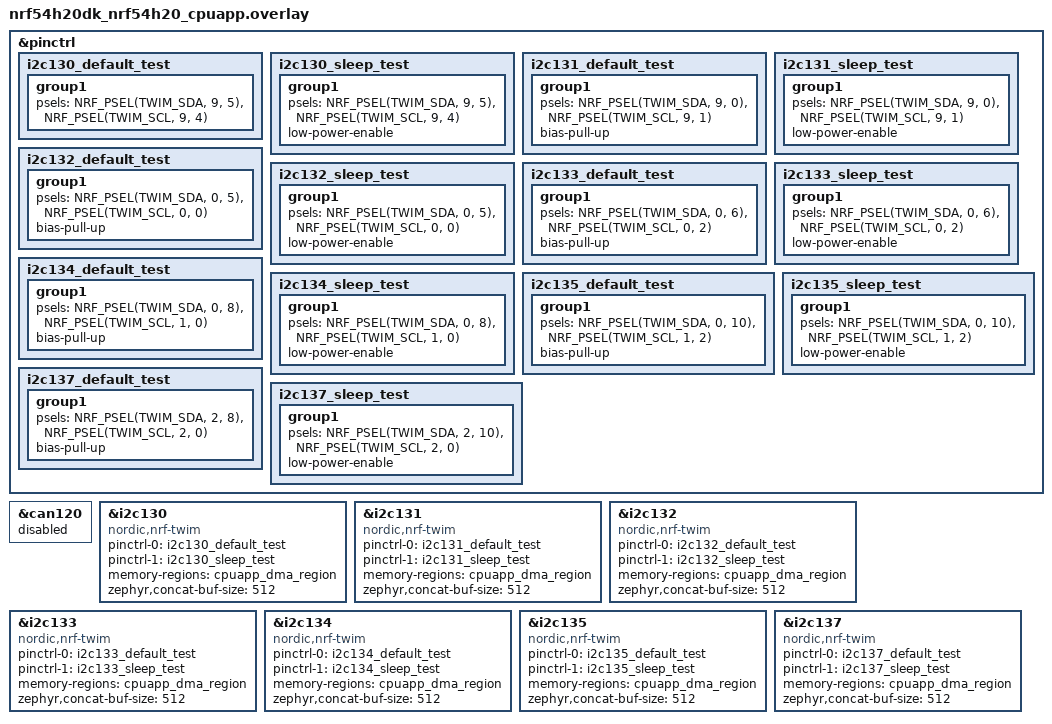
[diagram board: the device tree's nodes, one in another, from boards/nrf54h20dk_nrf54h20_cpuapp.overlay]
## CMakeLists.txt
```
# SPDX-License-Identifier: LicenseRef-Nordic-5-Clause

cmake_minimum_required(VERSION 3.20.0)

find_package(Zephyr REQUIRED HINTS $ENV{ZEPHYR_BASE})
project(twim_instances)

FILE(GLOB app_sources src/*.c)
target_sources(app PRIVATE ${app_sources})
```

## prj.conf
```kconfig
CONFIG_ZTEST=y
CONFIG_TEST_USERSPACE=y
CONFIG_I2C=y

CONFIG_I2C_TRANSFER_TIMEOUT_MS=100
```

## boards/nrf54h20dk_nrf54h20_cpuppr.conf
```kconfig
CONFIG_I2C_NRFX_TRANSFER_TIMEOUT=100
```

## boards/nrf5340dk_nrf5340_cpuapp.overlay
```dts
/*
 * Copyright (c) 2026 Nordic Semiconductor ASA
 *
 * SPDX-License-Identifier: LicenseRef-Nordic-5-Clause
 */

&pinctrl {
	i2c1_default_test: i2c1_default_test {
		group1 {
			psels = <NRF_PSEL(TWIM_SDA, 1, 6)>,
				<NRF_PSEL(TWIM_SCL, 1, 7)>;
			bias-pull-up;
		};
	};

	i2c1_sleep_test: i2c1_sleep_test {
		group1 {
			psels = <NRF_PSEL(TWIM_SDA, 1, 6)>,
				<NRF_PSEL(TWIM_SCL, 1, 7)>;
			low-power-enable;
		};
	};

	i2c2_default_test: i2c2_default_test {
		group1 {
			psels = <NRF_PSEL(TWIM_SDA, 1, 2)>,
				<NRF_PSEL(TWIM_SCL, 1, 3)>;
			bias-pull-up;
		};
	};

	i2c2_sleep_test: i2c2_sleep_test {
		group1 {
			psels = <NRF_PSEL(TWIM_SDA, 1, 2)>,
				<NRF_PSEL(TWIM_SCL, 1, 3)>;
			low-power-enable;
		};
	};

	i2c3_default_test: i2c3_default_test {
		group1 {
			psels = <NRF_PSEL(TWIM_SDA, 1, 4)>,
				<NRF_PSEL(TWIM_SCL, 1, 8)>;
			bias-pull-up;
		};
	};

	i2c3_sleep_test: i2c3_sleep_test {
		group1 {
			psels = <NRF_PSEL(TWIM_SDA, 1, 4)>,
				<NRF_PSEL(TWIM_SCL, 1, 8)>;
			low-power-enable;
		};
	};
};

&i2c1 {
	compatible = "nordic,nrf-twim";
	status = "okay";
	pinctrl-0 = <&i2c1_default_test>;
	pinctrl-1 = <&i2c1_sleep_test>;
	pinctrl-names = "default", "sleep";
};

&i2c2 {
	compatible = "nordic,nrf-twim";
	status = "okay";
	pinctrl-0 = <&i2c2_default_test>;
	pinctrl-1 = <&i2c2_sleep_test>;
	pinctrl-names = "default", "sleep";
};

&i2c3 {
	compatible = "nordic,nrf-twim";
	status = "okay";
	pinctrl-0 = <&i2c3_default_test>;
	pinctrl-1 = <&i2c3_sleep_test>;
	pinctrl-names = "default", "sleep";
};
```

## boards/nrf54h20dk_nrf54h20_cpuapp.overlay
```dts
/*
 * Copyright (c) 2025 Nordic Semiconductor ASA
 *
 * SPDX-License-Identifier: LicenseRef-Nordic-5-Clause
 */

&pinctrl {
	i2c130_default_test: i2c130_default_test {
		group1 {
			psels = <NRF_PSEL(TWIM_SDA, 9, 5)>,
				<NRF_PSEL(TWIM_SCL, 9, 4)>;
		};
	};

	i2c130_sleep_test: i2c130_sleep_test {
		group1 {
			psels = <NRF_PSEL(TWIM_SDA, 9, 5)>,
				<NRF_PSEL(TWIM_SCL, 9, 4)>;
			low-power-enable;
		};
	};

	i2c131_default_test: i2c131_default_test {
		group1 {
			psels = <NRF_PSEL(TWIM_SDA, 9, 0)>,
				<NRF_PSEL(TWIM_SCL, 9, 1)>;
			bias-pull-up;
		};
	};

	i2c131_sleep_test: i2c131_sleep_test {
		group1 {
			psels = <NRF_PSEL(TWIM_SDA, 9, 0)>,
				<NRF_PSEL(TWIM_SCL, 9, 1)>;
			low-power-enable;
		};
	};

	i2c132_default_test: i2c132_default_test {
		group1 {
			psels = <NRF_PSEL(TWIM_SDA, 0, 5)>,
				<NRF_PSEL(TWIM_SCL, 0, 0)>;
			bias-pull-up;
		};
	};

	i2c132_sleep_test: i2c132_sleep_test {
		group1 {
			psels = <NRF_PSEL(TWIM_SDA, 0, 5)>,
				<NRF_PSEL(TWIM_SCL, 0, 0)>;
			low-power-enable;
		};
	};

	i2c133_default_test: i2c133_default_test {
		group1 {
			psels = <NRF_PSEL(TWIM_SDA, 0, 6)>,
				<NRF_PSEL(TWIM_SCL, 0, 2)>;
			bias-pull-up;
		};
	};

	i2c133_sleep_test: i2c133_sleep_test {
		group1 {
			psels = <NRF_PSEL(TWIM_SDA, 0, 6)>,
				<NRF_PSEL(TWIM_SCL, 0, 2)>;
			low-power-enable;
		};
	};

	i2c134_default_test: i2c134_default_test {
		group1 {
			psels = <NRF_PSEL(TWIM_SDA, 0, 8)>,
				<NRF_PSEL(TWIM_SCL, 1, 0)>;
			bias-pull-up;
		};
	};

	i2c134_sleep_test: i2c134_sleep_test {
		group1 {
			psels = <NRF_PSEL(TWIM_SDA, 0, 8)>,
				<NRF_PSEL(TWIM_SCL, 1, 0)>;
			low-power-enable;
		};
	};

	i2c135_default_test: i2c135_default_test {
		group1 {
			psels = <NRF_PSEL(TWIM_SDA, 0, 10)>,
				<NRF_PSEL(TWIM_SCL, 1, 2)>;
			bias-pull-up;
		};
	};

	i2c135_sleep_test: i2c135_sleep_test {
		group1 {
			psels = <NRF_PSEL(TWIM_SDA, 0, 10)>,
				<NRF_PSEL(TWIM_SCL, 1, 2)>;
			low-power-enable;
		};
	};

	i2c137_default_test: i2c137_default_test {
		group1 {
			psels = <NRF_PSEL(TWIM_SDA, 2, 8)>,
				<NRF_PSEL(TWIM_SCL, 2, 0)>;
			bias-pull-up;
		};
	};

	i2c137_sleep_test: i2c137_sleep_test {
		group1 {
			psels = <NRF_PSEL(TWIM_SDA, 2, 10)>,
				<NRF_PSEL(TWIM_SCL, 2, 0)>;
			low-power-enable;
		};
	};
};

&can120 {
	status = "disabled";
};

&i2c130 {
	compatible = "nordic,nrf-twim";
	status = "okay";
	pinctrl-0 = <&i2c130_default_test>;
	pinctrl-1 = <&i2c130_sleep_test>;
	pinctrl-names = "default", "sleep";
	memory-regions = <&cpuapp_dma_region>;
	zephyr,concat-buf-size = <512>;
};

&i2c131 {
	compatible = "nordic,nrf-twim";
	status = "okay";
	pinctrl-0 = <&i2c131_default_test>;
	pinctrl-1 = <&i2c131_sleep_test>;
	pinctrl-names = "default", "sleep";
	memory-regions = <&cpuapp_dma_region>;
	zephyr,concat-buf-size = <512>;
};

&i2c132 {
	compatible = "nordic,nrf-twim";
	status = "okay";
	pinctrl-0 = <&i2c132_default_test>;
	pinctrl-1 = <&i2c132_sleep_test>;
	pinctrl-names = "default", "sleep";
	memory-regions = <&cpuapp_dma_region>;
	zephyr,concat-buf-size = <512>;
};

&i2c133 {
	compatible = "nordic,nrf-twim";
	status = "okay";
	pinctrl-0 = <&i2c133_default_test>;
	pinctrl-1 = <&i2c133_sleep_test>;
	pinctrl-names = "default", "sleep";
	memory-regions = <&cpuapp_dma_region>;
	zephyr,concat-buf-size = <512>;
};

&i2c134 {
	compatible = "nordic,nrf-twim";
	status = "okay";
	pinctrl-0 = <&i2c134_default_test>;
	pinctrl-1 = <&i2c134_sleep_test>;
	pinctrl-names = "default", "sleep";
	memory-regions = <&cpuapp_dma_region>;
	zephyr,concat-buf-size = <512>;
};

&i2c135 {
	compatible = "nordic,nrf-twim";
	status = "okay";
	pinctrl-0 = <&i2c135_default_test>;
	pinctrl-1 = <&i2c135_sleep_test>;
	pinctrl-names = "default", "sleep";
	memory-regions = <&cpuapp_dma_region>;
	zephyr,concat-buf-size = <512>;
};

/* i2c136 inaccessible due to console on uart136 */

&i2c137 {
	compatible = "nordic,nrf-twim";
	status = "okay";
	pinctrl-0 = <&i2c137_default_test>;
	pinctrl-1 = <&i2c137_sleep_test>;
	pinctrl-names = "default", "sleep";
	memory-regions = <&cpuapp_dma_region>;
	zephyr,concat-buf-size = <512>;
};
```

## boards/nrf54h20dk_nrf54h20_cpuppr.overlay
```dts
/*
 * Copyright (c) 2025 Nordic Semiconductor ASA
 *
 * SPDX-License-Identifier: LicenseRef-Nordic-5-Clause
 */

&pinctrl {
	i2c130_default_test: i2c130_default_test {
		group1 {
			psels = <NRF_PSEL(TWIM_SDA, 9, 5)>,
				<NRF_PSEL(TWIM_SCL, 9, 4)>;
		};
	};

	i2c130_sleep_test: i2c130_sleep_test {
		group1 {
			psels = <NRF_PSEL(TWIM_SDA, 9, 5)>,
				<NRF_PSEL(TWIM_SCL, 9, 4)>;
			low-power-enable;
		};
	};

	i2c131_default_test: i2c131_default_test {
		group1 {
			psels = <NRF_PSEL(TWIM_SDA, 9, 0)>,
				<NRF_PSEL(TWIM_SCL, 9, 1)>;
			bias-pull-up;
		};
	};

	i2c131_sleep_test: i2c131_sleep_test {
		group1 {
			psels = <NRF_PSEL(TWIM_SDA, 9, 0)>,
				<NRF_PSEL(TWIM_SCL, 9, 1)>;
			low-power-enable;
		};
	};

	i2c132_default_test: i2c132_default_test {
		group1 {
			psels = <NRF_PSEL(TWIM_SDA, 0, 5)>,
				<NRF_PSEL(TWIM_SCL, 0, 0)>;
			bias-pull-up;
		};
	};

	i2c132_sleep_test: i2c132_sleep_test {
		group1 {
			psels = <NRF_PSEL(TWIM_SDA, 0, 5)>,
				<NRF_PSEL(TWIM_SCL, 0, 0)>;
			low-power-enable;
		};
	};

	i2c133_default_test: i2c133_default_test {
		group1 {
			psels = <NRF_PSEL(TWIM_SDA, 0, 6)>,
				<NRF_PSEL(TWIM_SCL, 0, 2)>;
			bias-pull-up;
		};
	};

	i2c133_sleep_test: i2c133_sleep_test {
		group1 {
			psels = <NRF_PSEL(TWIM_SDA, 0, 6)>,
				<NRF_PSEL(TWIM_SCL, 0, 2)>;
			low-power-enable;
		};
	};

	i2c134_default_test: i2c134_default_test {
		group1 {
			psels = <NRF_PSEL(TWIM_SDA, 0, 8)>,
				<NRF_PSEL(TWIM_SCL, 1, 0)>;
			bias-pull-up;
		};
	};

	i2c134_sleep_test: i2c134_sleep_test {
		group1 {
			psels = <NRF_PSEL(TWIM_SDA, 0, 8)>,
				<NRF_PSEL(TWIM_SCL, 1, 0)>;
			low-power-enable;
		};
	};

	i2c137_default_test: i2c137_default_test {
		group1 {
			psels = <NRF_PSEL(TWIM_SDA, 2, 8)>,
				<NRF_PSEL(TWIM_SCL, 2, 0)>;
			bias-pull-up;
		};
	};

	i2c137_sleep_test: i2c137_sleep_test {
		group1 {
			psels = <NRF_PSEL(TWIM_SDA, 2, 10)>,
				<NRF_PSEL(TWIM_SCL, 2, 0)>;
			low-power-enable;
		};
	};
};

&i2c130 {
	compatible = "nordic,nrf-twim";
	status = "okay";
	pinctrl-0 = <&i2c130_default_test>;
	pinctrl-1 = <&i2c130_sleep_test>;
	pinctrl-names = "default", "sleep";
	zephyr,concat-buf-size = <256>;
};

&i2c131 {
	compatible = "nordic,nrf-twim";
	status = "okay";
	pinctrl-0 = <&i2c131_default_test>;
	pinctrl-1 = <&i2c131_sleep_test>;
	pinctrl-names = "default", "sleep";
	zephyr,concat-buf-size = <256>;
};

&i2c132 {
	compatible = "nordic,nrf-twim";
	status = "okay";
	pinctrl-0 = <&i2c132_default_test>;
	pinctrl-1 = <&i2c132_sleep_test>;
	pinctrl-names = "default", "sleep";
	zephyr,concat-buf-size = <256>;
};

&i2c133 {
	compatible = "nordic,nrf-twim";
	status = "okay";
	pinctrl-0 = <&i2c133_default_test>;
	pinctrl-1 = <&i2c133_sleep_test>;
	pinctrl-names = "default", "sleep";
	zephyr,concat-buf-size = <256>;
};

&i2c134 {
	compatible = "nordic,nrf-twim";
	status = "okay";
	pinctrl-0 = <&i2c134_default_test>;
	pinctrl-1 = <&i2c134_sleep_test>;
	pinctrl-names = "default", "sleep";
	zephyr,concat-buf-size = <256>;
};

/* i2c135 inaccessible due to cpuppr console on uart135 */

/* i2c136 inaccessible due to cpuapp console on uart136 */

&i2c137 {
	compatible = "nordic,nrf-twim";
	status = "okay";
	pinctrl-0 = <&i2c134_default_test>;
	pinctrl-1 = <&i2c134_sleep_test>;
	pinctrl-names = "default", "sleep";
	zephyr,concat-buf-size = <256>;
};
```

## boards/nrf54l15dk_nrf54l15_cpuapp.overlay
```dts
/*
 * Copyright (c) 2025 Nordic Semiconductor ASA
 *
 * SPDX-License-Identifier: LicenseRef-Nordic-5-Clause
 */

&pinctrl {
	i2c21_default_test: i2c21_default_test {
		group1 {
			psels = <NRF_PSEL(TWIM_SDA, 1, 8)>,
				<NRF_PSEL(TWIM_SCL, 1, 9)>;
			bias-pull-up;
		};
	};

	i2c21_sleep_test: i2c21_sleep_test {
		group1 {
			psels = <NRF_PSEL(TWIM_SDA, 1, 8)>,
				<NRF_PSEL(TWIM_SCL, 1, 9)>;
			low-power-enable;
		};
	};

	i2c22_default_test: i2c22_default_test {
		group1 {
			psels = <NRF_PSEL(TWIM_SDA, 1, 10)>,
				<NRF_PSEL(TWIM_SCL, 1, 12)>;
			bias-pull-up;
		};
	};

	i2c22_sleep_test: i2c22_sleep_test {
		group1 {
			psels = <NRF_PSEL(TWIM_SDA, 1, 10)>,
				<NRF_PSEL(TWIM_SCL, 1, 12)>;
			low-power-enable;
		};
	};

	i2c30_default_test: i2c30_default_test {
		group1 {
			psels = <NRF_PSEL(TWIM_SDA, 0, 0)>,
				<NRF_PSEL(TWIM_SCL, 0, 2)>;
			bias-pull-up;
		};
	};

	i2c30_sleep_test: i2c30_sleep_test {
		group1 {
			psels = <NRF_PSEL(TWIM_SDA, 0, 0)>,
				<NRF_PSEL(TWIM_SCL, 0, 2)>;
			low-power-enable;
		};
	};
};

&uicr {
	nfct-pins-as-gpios;
};

/* i2c20 inaccessible due to console on uart20 */

&i2c21 {
	compatible = "nordic,nrf-twim";
	status = "okay";
	pinctrl-0 = <&i2c21_default_test>;
	pinctrl-1 = <&i2c21_sleep_test>;
	pinctrl-names = "default", "sleep";
};

&i2c22 {
	compatible = "nordic,nrf-twim";
	status = "okay";
	pinctrl-0 = <&i2c22_default_test>;
	pinctrl-1 = <&i2c22_sleep_test>;
	pinctrl-names = "default", "sleep";
};

&i2c30 {
	compatible = "nordic,nrf-twim";
	status = "okay";
	pinctrl-0 = <&i2c30_default_test>;
	pinctrl-1 = <&i2c30_sleep_test>;
	pinctrl-names = "default", "sleep";
};
```

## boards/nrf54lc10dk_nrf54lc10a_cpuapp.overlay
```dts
/*
 * Copyright (c) 2026 Nordic Semiconductor ASA
 *
 * SPDX-License-Identifier: LicenseRef-Nordic-5-Clause
 *
 * nRF54LC10 DK: P1.8 / P1.10 are used by buttons / LED — use P1.11 / P1.13 for second TWIM.
 */

&pinctrl {
	i2c20_default_test: i2c20_default_test {
		group1 {
			psels = <NRF_PSEL(TWIM_SDA, 1, 0)>,
				<NRF_PSEL(TWIM_SCL, 1, 2)>;
			bias-pull-up;
		};
	};

	i2c20_sleep_test: i2c20_sleep_test {
		group1 {
			psels = <NRF_PSEL(TWIM_SDA, 1, 0)>,
				<NRF_PSEL(TWIM_SCL, 1, 2)>;
			low-power-enable;
		};
	};

	i2c21_default_test: i2c21_default_test {
		group1 {
			psels = <NRF_PSEL(TWIM_SDA, 1, 11)>,
				<NRF_PSEL(TWIM_SCL, 1, 13)>;
		};
	};

	i2c21_sleep_test: i2c21_sleep_test {
		group1 {
			psels = <NRF_PSEL(TWIM_SDA, 1, 11)>,
				<NRF_PSEL(TWIM_SCL, 1, 13)>;
			low-power-enable;
		};
	};
};

&i2c20 {
	compatible = "nordic,nrf-twim";
	status = "okay";
	pinctrl-0 = <&i2c20_default_test>;
	pinctrl-1 = <&i2c20_sleep_test>;
	pinctrl-names = "default", "sleep";
};

&i2c21 {
	compatible = "nordic,nrf-twim";
	status = "okay";
	pinctrl-0 = <&i2c21_default_test>;
	pinctrl-1 = <&i2c21_sleep_test>;
	pinctrl-names = "default", "sleep";
};

/* i2c30 inaccessible due to console on uart30 */
```

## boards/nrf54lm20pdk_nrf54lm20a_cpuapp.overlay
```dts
/*
 * Copyright (c) 2025 Nordic Semiconductor ASA
 *
 * SPDX-License-Identifier: LicenseRef-Nordic-5-Clause
 */

&pinctrl {
	i2c21_default_test: i2c21_default_test {
		group1 {
			psels = <NRF_PSEL(TWIM_SDA, 3, 0)>,
				<NRF_PSEL(TWIM_SCL, 3, 1)>;
		};
	};

	i2c21_sleep_test: i2c21_sleep_test {
		group1 {
			psels = <NRF_PSEL(TWIM_SDA, 3, 0)>,
				<NRF_PSEL(TWIM_SCL, 3, 1)>;
			low-power-enable;
		};
	};

	i2c22_default_test: i2c22_default_test {
		group1 {
			psels = <NRF_PSEL(TWIM_SDA, 3, 2)>,
				<NRF_PSEL(TWIM_SCL, 3, 3)>;
			bias-pull-up;
		};
	};

	i2c22_sleep_test: i2c22_sleep_test {
		group1 {
			psels = <NRF_PSEL(TWIM_SDA, 3, 2)>,
				<NRF_PSEL(TWIM_SCL, 3, 3)>;
			low-power-enable;
		};
	};

	i2c23_default_test: i2c23_default_test {
		group1 {
			psels = <NRF_PSEL(TWIM_SDA, 3, 4)>,
				<NRF_PSEL(TWIM_SCL, 3, 5)>;
			bias-pull-up;
		};
	};

	i2c23_sleep_test: i2c23_sleep_test {
		group1 {
			psels = <NRF_PSEL(TWIM_SDA, 3, 4)>,
				<NRF_PSEL(TWIM_SCL, 3, 5)>;
			low-power-enable;
		};
	};

	i2c24_default_test: i2c24_default_test {
		group1 {
			psels = <NRF_PSEL(TWIM_SDA, 3, 6)>,
				<NRF_PSEL(TWIM_SCL, 3, 7)>;
			bias-pull-up;
		};
	};

	i2c24_sleep_test: i2c24_sleep_test {
		group1 {
			psels = <NRF_PSEL(TWIM_SDA, 3, 6)>,
				<NRF_PSEL(TWIM_SCL, 3, 7)>;
			low-power-enable;
		};
	};

	i2c30_default_test: i2c30_default_test {
		group1 {
			psels = <NRF_PSEL(TWIM_SDA, 0, 0)>,
				<NRF_PSEL(TWIM_SCL, 0, 5)>;
			bias-pull-up;
		};
	};

	i2c30_sleep_test: i2c30_sleep_test {
		group1 {
			psels = <NRF_PSEL(TWIM_SDA, 0, 0)>,
				<NRF_PSEL(TWIM_SCL, 0, 5)>;
			low-power-enable;
		};
	};
};

/* i2c20 inaccessible due to console on uart20 */

&i2c21 {
	compatible = "nordic,nrf-twim";
	status = "okay";
	pinctrl-0 = <&i2c21_default_test>;
	pinctrl-1 = <&i2c21_sleep_test>;
	pinctrl-names = "default", "sleep";
};

&i2c22 {
	compatible = "nordic,nrf-twim";
	status = "okay";
	pinctrl-0 = <&i2c22_default_test>;
	pinctrl-1 = <&i2c22_sleep_test>;
	pinctrl-names = "default", "sleep";
};

&i2c23 {
	compatible = "nordic,nrf-twim";
	status = "okay";
	pinctrl-0 = <&i2c23_default_test>;
	pinctrl-1 = <&i2c23_sleep_test>;
	pinctrl-names = "default", "sleep";
};

&i2c24 {
	compatible = "nordic,nrf-twim";
	status = "okay";
	pinctrl-0 = <&i2c24_default_test>;
	pinctrl-1 = <&i2c24_sleep_test>;
	pinctrl-names = "default", "sleep";
};

&i2c30 {
	compatible = "nordic,nrf-twim";
	status = "okay";
	pinctrl-0 = <&i2c30_default_test>;
	pinctrl-1 = <&i2c30_sleep_test>;
	pinctrl-names = "default", "sleep";
};
```

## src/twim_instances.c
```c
/*
 * Copyright (c) 2025, Nordic Semiconductor ASA
 *
 * SPDX-License-Identifier: LicenseRef-Nordic-5-Clause
 */

#include <zephyr/kernel.h>
#include <zephyr/drivers/i2c.h>
#include <zephyr/ztest.h>

#include <zephyr/logging/log.h>
LOG_MODULE_REGISTER(test);

#define DEVICE_DT_GET_AND_COMMA(node_id) DEVICE_DT_GET(node_id),
/* Generate a list of devices for all instances of the "compat" */
#define DEVS_FOR_DT_COMPAT(compat) \
	DT_FOREACH_STATUS_OKAY(compat, DEVICE_DT_GET_AND_COMMA)

static const struct device *const devices[] = {
#ifdef CONFIG_I2C_NRFX_TWIM
	DEVS_FOR_DT_COMPAT(nordic_nrf_twim)
#endif
};

typedef void (*test_func_t)(const struct device *dev);
typedef bool (*capability_func_t)(const struct device *dev);

static void setup_instance(const struct device *dev)
{
	/* Left for future test expansion. */
}

static void tear_down_instance(const struct device *dev)
{
	/* Left for future test expansion. */
}

static void test_all_instances(test_func_t func, capability_func_t capability_check)
{
	int devices_skipped = 0;

	zassert_true(ARRAY_SIZE(devices) > 0, "No device found");
	for (int i = 0; i < ARRAY_SIZE(devices); i++) {
		setup_instance(devices[i]);
		TC_PRINT("\nInstance %u: ", i + 1);
		if ((capability_check == NULL) ||
		     capability_check(devices[i])) {
			TC_PRINT("Testing %s\n", devices[i]->name);
			func(devices[i]);
		} else {
			TC_PRINT("Skipped for %s\n", devices[i]->name);
			devices_skipped++;
		}
		tear_down_instance(devices[i]);
		/* Allow logs to be printed. */
		k_sleep(K_MSEC(100));
	}
	if (devices_skipped == ARRAY_SIZE(devices)) {
		ztest_test_skip();
	}
}


/**
 * Test validates if instance can be configured.
 */
static void test_configure_instance(const struct device *dev)
{
	uint32_t i2c_config = I2C_SPEED_SET(I2C_SPEED_STANDARD) | I2C_MODE_CONTROLLER;
	uint8_t i2c_tx_buffer[1] = {255};
	int ret = 0;

	ret = i2c_configure(dev, i2c_config);
	zassert_equal(0, ret, "%s: i2c_configure() failed (%d)", dev->name, ret);

	/* Returns error (-EIO or -ETIMEDOUT) as there is no device connnected to the I2C bus. */
	ret = i2c_write(dev, i2c_tx_buffer, sizeof(i2c_tx_buffer), 0xFF);
	zassert_true((ret == -EIO) || (ret == -ETIMEDOUT),
		     "%s: i2c_write() failed (%d)", dev->name, ret);
}


/**
 * Test if any unexpected device can be detected on instance bus.
 * SMBus and i2c scan shell command based.
 */
static void test_scan_instance(const struct device *dev)
{
	uint8_t first_addr = 0x00, last_addr = 0x7F;
	uint8_t dev_cnt = 0;

	struct i2c_msg msg = {
		.buf   = NULL,
		.len   = 0U,
		.flags = I2C_MSG_WRITE | I2C_MSG_STOP
	};

	for (uint8_t addr = first_addr; addr <= last_addr; addr += 1) {
		if (i2c_transfer(dev, &msg, 1, addr) == 0) {
			dev_cnt = dev_cnt + 1;
			TC_PRINT("Found device with address: 0x%x\n", addr);
		}
	}
	zassert_equal(dev_cnt, 0,
		"i2c scan found %d unexpected devices on %s bus\n",
		dev_cnt, dev->name);
}

static bool test_configure_capable(const struct device *dev)
{
	return true;
}

ZTEST(twim_instances, test_configure)
{
	test_all_instances(test_configure_instance, test_configure_capable);
}

ZTEST(twim_instances, test_scan)
{
	test_all_instances(test_scan_instance, test_configure_capable);
}

static void *suite_setup(void)
{
	int i;

	for (i = 0; i < ARRAY_SIZE(devices); i++) {
		zassert_true(device_is_ready(devices[i]),
			     "Device %s is not ready", devices[i]->name);
		k_object_access_grant(devices[i], k_current_get());
	}

	return NULL;
}

ZTEST_SUITE(twim_instances, NULL, suite_setup, NULL, NULL, NULL);
```
